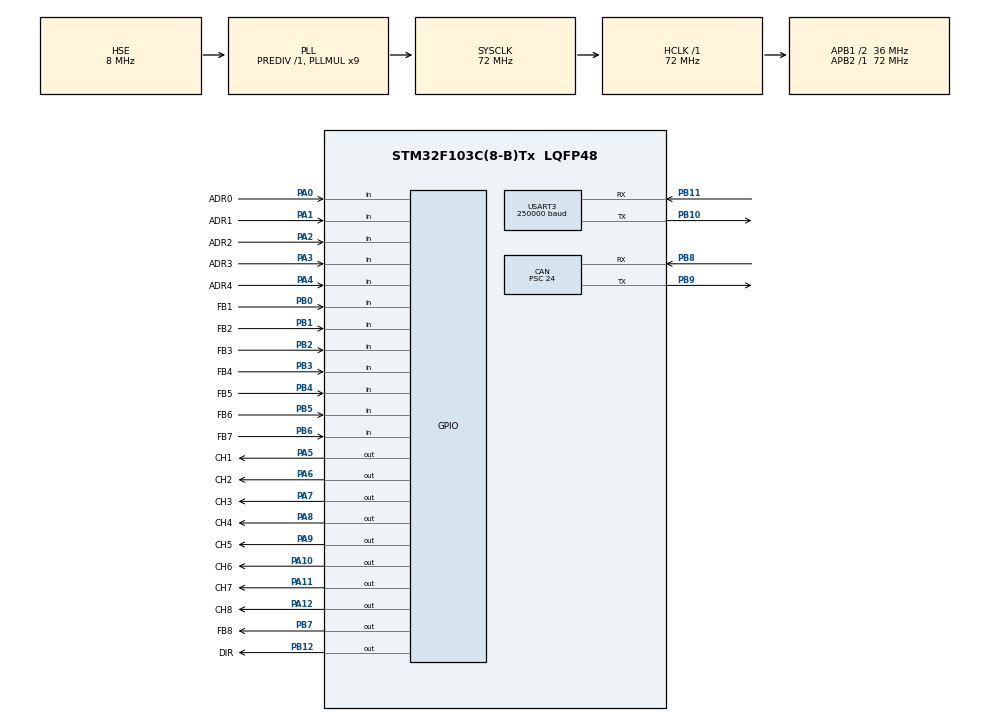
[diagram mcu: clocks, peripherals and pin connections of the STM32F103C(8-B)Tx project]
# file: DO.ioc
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CAN.CalculateBaudRate=500000
CAN.CalculateTimeBit=1999.99
CAN.CalculateTimeQuantum=666.6666666666667
CAN.Prescaler=24
Mcu.Family=STM32F1
Mcu.Name=STM32F103C(8-B)Tx
Mcu.Package=LQFP48
NVIC.PriorityGroup=NVIC_PRIORITYGROUP_4
PA0-WKUP.GPIO_Label=ADR0
PA0-WKUP.Signal=GPIO_Input
PA1.GPIO_Label=ADR1
PA1.Signal=GPIO_Input
PA10.GPIO_Label=CH6
PA10.Signal=GPIO_Output
PA11.GPIO_Label=CH7
PA11.Signal=GPIO_Output
PA12.GPIO_Label=CH8
PA12.Signal=GPIO_Output
PA13.Mode=Serial_Wire
PA13.Signal=SYS_JTMS-SWDIO
PA14.Mode=Serial_Wire
PA14.Signal=SYS_JTCK-SWCLK
PA2.GPIO_Label=ADR2
PA2.Signal=GPIO_Input
PA3.GPIO_Label=ADR3
PA3.Signal=GPIO_Input
PA4.GPIO_Label=ADR4
PA4.Signal=GPIO_Input
PA5.GPIO_Label=CH1
PA5.Signal=GPIO_Output
PA6.GPIO_Label=CH2
PA6.Signal=GPIO_Output
PA7.GPIO_Label=CH3
PA7.Signal=GPIO_Output
PA8.GPIO_Label=CH4
PA8.Signal=GPIO_Output
PA9.GPIO_Label=CH5
PA9.Signal=GPIO_Output
PB0.GPIO_Label=FB1
PB0.Signal=GPIO_Input
PB1.GPIO_Label=FB2
PB1.Signal=GPIO_Input
PB10.Mode=Asynchronous
PB10.Signal=USART3_TX
PB11.Mode=Asynchronous
PB11.Signal=USART3_RX
PB12.GPIO_Label=DIR
PB12.Signal=GPIO_Output
PB2.GPIO_Label=FB3
PB2.Signal=GPIO_Input
PB3.GPIO_Label=FB4
PB3.Signal=GPIO_Input
PB4.GPIO_Label=FB5
PB4.Signal=GPIO_Input
PB5.GPIO_Label=FB6
PB5.Signal=GPIO_Input
PB6.GPIO_Label=FB7
PB6.Signal=GPIO_Input
PB7.GPIO_Label=FB8
PB7.Signal=GPIO_Output
PB8.Mode=CAN_Activate
PB8.Signal=CAN_RX
PB9.Mode=CAN_Activate
PB9.Signal=CAN_TX
PD0-OSC_IN.Mode=HSE-External-Oscillator
PD0-OSC_IN.Signal=RCC_OSC_IN
PD1-OSC_OUT.Mode=HSE-External-Oscillator
PD1-OSC_OUT.Signal=RCC_OSC_OUT
ProjectManager.HeapSize=0x200
ProjectManager.StackSize=0x400
ProjectManager.TargetToolchain=STM32CubeIDE
RCC.AHBFreq_Value=72000000
RCC.APB1CLKDivider=RCC_HCLK_DIV2
RCC.APB1Freq_Value=36000000
RCC.APB1TimFreq_Value=72000000
RCC.APB2Freq_Value=72000000
RCC.APB2TimFreq_Value=72000000
RCC.HCLKFreq_Value=72000000
RCC.PLLMUL=RCC_PLL_MUL9
RCC.PLLSourceVirtual=RCC_PLLSOURCE_HSE
RCC.SYSCLKFreq_VALUE=72000000
RCC.SYSCLKSource=RCC_SYSCLKSOURCE_PLLCLK
RCC.USBFreq_Value=72000000
USART3.BaudRate=250000
USART3.VirtualMode=VM_ASYNC
USART3.WordLength=WORDLENGTH_8B
VP_CRC_VS_CRC.Mode=CRC_Activate
board=custom

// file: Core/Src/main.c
/* USER CODE BEGIN Header */
/**
  ******************************************************************************
  * @file           : main.c
  * @brief          : Main program body
  ******************************************************************************
  * @attention
  *
  * <h2><center>&copy; Copyright (c) 2021 STMicroelectronics.
  * All rights reserved.</center></h2>
  *
  * This software component is licensed by ST under BSD 3-Clause license,
  * the "License"; You may not use this file except in compliance with the
  * License. You may obtain a copy of the License at:
  *                        opensource.org/licenses/BSD-3-Clause
  *
  ******************************************************************************
  */
/* USER CODE END Header */
#include "main.h"
#include "can.h"
#include "crc.h"
#include "usart.h"
#include "gpio.h"

void SystemClock_Config(void);

int main(void)
{

  /* MCU Configuration--------------------------------------------------------*/

  /* Reset of all peripherals, Initializes the Flash interface and the Systick. */
  HAL_Init();

  /* Configure the system clock */
  SystemClock_Config();

  /* Initialize all configured peripherals */
  MX_GPIO_Init();
  MX_CAN_Init();
  MX_CRC_Init();
  MX_USART3_UART_Init();

  /* Infinite loop */
  while (1)
  {

    /* USER CODE BEGIN 3 */

	HAL_GPIO_WritePin(GPIOA, 0x1FE0, 1);
	HAL_Delay(100);
	HAL_GPIO_WritePin(GPIOA, 0x1FE0, 0);
	HAL_Delay(100);
  }
  /* USER CODE END 3 */
}

void SystemClock_Config(void)
{
  RCC_OscInitTypeDef RCC_OscInitStruct = {0};
  RCC_ClkInitTypeDef RCC_ClkInitStruct = {0};

  /** Initializes the RCC Oscillators according to the specified parameters
  * in the RCC_OscInitTypeDef structure.
  */
  RCC_OscInitStruct.OscillatorType = RCC_OSCILLATORTYPE_HSE;
  RCC_OscInitStruct.HSEState = RCC_HSE_ON;
  RCC_OscInitStruct.HSEPredivValue = RCC_HSE_PREDIV_DIV1;
  RCC_OscInitStruct.HSIState = RCC_HSI_ON;
  RCC_OscInitStruct.PLL.PLLState = RCC_PLL_ON;
  RCC_OscInitStruct.PLL.PLLSource = RCC_PLLSOURCE_HSE;
  RCC_OscInitStruct.PLL.PLLMUL = RCC_PLL_MUL9;
  if (HAL_RCC_OscConfig(&RCC_OscInitStruct) != HAL_OK)
  {
    Error_Handler();
  }
  /** Initializes the CPU, AHB and APB buses clocks
  */
  RCC_ClkInitStruct.ClockType = RCC_CLOCKTYPE_HCLK|RCC_CLOCKTYPE_SYSCLK
                              |RCC_CLOCKTYPE_PCLK1|RCC_CLOCKTYPE_PCLK2;
  RCC_ClkInitStruct.SYSCLKSource = RCC_SYSCLKSOURCE_PLLCLK;
  RCC_ClkInitStruct.AHBCLKDivider = RCC_SYSCLK_DIV1;
  RCC_ClkInitStruct.APB1CLKDivider = RCC_HCLK_DIV2;
  RCC_ClkInitStruct.APB2CLKDivider = RCC_HCLK_DIV1;

  if (HAL_RCC_ClockConfig(&RCC_ClkInitStruct, FLASH_LATENCY_2) != HAL_OK)
  {
    Error_Handler();
  }
}

void Error_Handler(void)
{
  __disable_irq();
  while (1)
  {
  }
}

/************************ (C) COPYRIGHT STMicroelectronics *****END OF FILE****/
